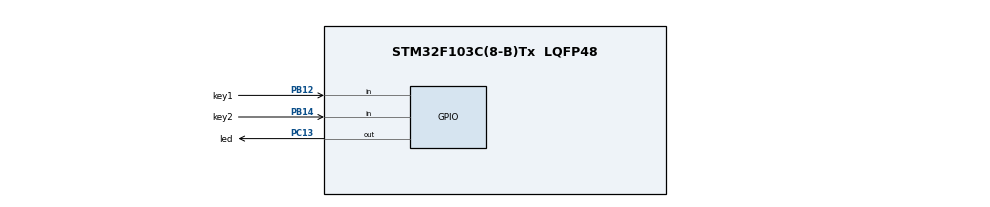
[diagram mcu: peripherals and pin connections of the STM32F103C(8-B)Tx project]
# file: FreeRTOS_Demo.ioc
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Mcu.Family=STM32F1
Mcu.Name=STM32F103C(8-B)Tx
Mcu.Package=LQFP48
NVIC.PriorityGroup=NVIC_PRIORITYGROUP_4
NVIC.TIM4_IRQn=true\:15\:0\:false\:false\:true\:false\:true\:true
NVIC.TimeBase=TIM4_IRQn
NVIC.TimeBaseIP=TIM4
PA13.Mode=Serial_Wire
PA13.Signal=SYS_JTMS-SWDIO
PA14.Mode=Serial_Wire
PA14.Signal=SYS_JTCK-SWCLK
PB12.GPIO_Label=key1
PB12.GPIO_PuPd=GPIO_PULLUP
PB12.Signal=GPIO_Input
PB14.GPIO_Label=key2
PB14.GPIO_PuPd=GPIO_PULLUP
PB14.Signal=GPIO_Input
PC13-TAMPER-RTC.GPIO_Label=led
PC13-TAMPER-RTC.GPIO_PuPd=GPIO_PULLUP
PC13-TAMPER-RTC.PinState=GPIO_PIN_SET
PC13-TAMPER-RTC.Signal=GPIO_Output
PD0-OSC_IN.Mode=HSE-External-Oscillator
PD0-OSC_IN.Signal=RCC_OSC_IN
PD1-OSC_OUT.Mode=HSE-External-Oscillator
PD1-OSC_OUT.Signal=RCC_OSC_OUT
ProjectManager.HeapSize=0x200
ProjectManager.StackSize=0x400
ProjectManager.TargetToolchain=CMake
RCC.AHBFreq_Value=72000000
RCC.APB1CLKDivider=RCC_HCLK_DIV2
RCC.APB1Freq_Value=36000000
RCC.APB1TimFreq_Value=72000000
RCC.APB2Freq_Value=72000000
RCC.APB2TimFreq_Value=72000000
RCC.HCLKFreq_Value=72000000
RCC.PLLMUL=RCC_PLL_MUL9
RCC.PLLSourceVirtual=RCC_PLLSOURCE_HSE
RCC.SYSCLKFreq_VALUE=72000000
RCC.SYSCLKSource=RCC_SYSCLKSOURCE_PLLCLK
RCC.USBFreq_Value=72000000
VP_SYS_VS_tim4.Mode=TIM4
board=custom

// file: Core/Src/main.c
/* USER CODE BEGIN Header */
/**
  ******************************************************************************
  * @file           : main.c
  * @brief          : Main program body
  ******************************************************************************
  * @attention
  *
  * Copyright (c) 2026 STMicroelectronics.
  * All rights reserved.
  *
  * This software is licensed under terms that can be found in the LICENSE file
  * in the root directory of this software component.
  * If no LICENSE file comes with this software, it is provided AS-IS.
  *
  ******************************************************************************
  */
/* USER CODE END Header */
#include "main.h"
#include "gpio.h"

void SystemClock_Config(void);

int main(void)
{

  /* MCU Configuration--------------------------------------------------------*/

  /* Reset of all peripherals, Initializes the Flash interface and the Systick. */
  HAL_Init();

  /* Configure the system clock */
  SystemClock_Config();

  /* Initialize all configured peripherals */
  MX_GPIO_Init();
  /* USER CODE BEGIN 2 */
  /* DWT 延时初始化（delay.h 中 USE_DWT_DELAY = 1） */
  DWT_Init();

  /* 按键初始化：初始化 multi_button 对象并绑定单击事件 */
  KEY_Init();

  /* 创建任务并启动 FreeRTOS 调度器（不返回） */
  freertos_start();
  /* USER CODE END 2 */

  /* Infinite loop */
  while (1)
  {

  }
}

void SystemClock_Config(void)
{
  LL_FLASH_SetLatency(LL_FLASH_LATENCY_2);
  while(LL_FLASH_GetLatency()!= LL_FLASH_LATENCY_2)
  {
  }
  LL_RCC_HSE_Enable();

   /* Wait till HSE is ready */
  while(LL_RCC_HSE_IsReady() != 1)
  {

  }
  LL_RCC_PLL_ConfigDomain_SYS(LL_RCC_PLLSOURCE_HSE_DIV_1, LL_RCC_PLL_MUL_9);
  LL_RCC_PLL_Enable();

   /* Wait till PLL is ready */
  while(LL_RCC_PLL_IsReady() != 1)
  {

  }
  LL_RCC_SetAHBPrescaler(LL_RCC_SYSCLK_DIV_1);
  LL_RCC_SetAPB1Prescaler(LL_RCC_APB1_DIV_2);
  LL_RCC_SetAPB2Prescaler(LL_RCC_APB2_DIV_1);
  LL_RCC_SetSysClkSource(LL_RCC_SYS_CLKSOURCE_PLL);

   /* Wait till System clock is ready */
  while(LL_RCC_GetSysClkSource() != LL_RCC_SYS_CLKSOURCE_STATUS_PLL)
  {

  }
  LL_SetSystemCoreClock(72000000);

   /* Update the time base */
  if (HAL_InitTick (TICK_INT_PRIORITY) != HAL_OK)
  {
    Error_Handler();
  }
}

void HAL_TIM_PeriodElapsedCallback(TIM_HandleTypeDef *htim)
{
  if (htim->Instance == TIM4)
  {
    HAL_IncTick();
  }
}

void Error_Handler(void)
{
  __disable_irq();
  while (1)
  {
  }
}
